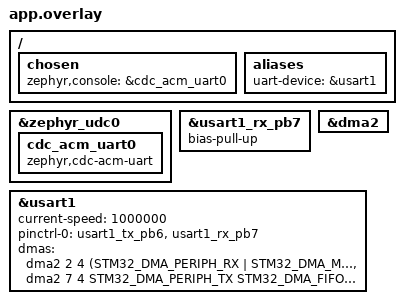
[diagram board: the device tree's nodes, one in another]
/*
 * Copyright (c) 2021 Nordic Semiconductor ASA
 *
 * SPDX-License-Identifier: Apache-2.0
 */

#include <zephyr/dt-bindings/dma/stm32_dma.h>

/ {
	chosen {
		zephyr,console = &cdc_acm_uart0;
	};

	aliases {
    	uart-device = &usart1;
    };
};

/*
&usbotg_fs {
    status = "okay";
    cdc_acm_uart0: cdc_acm_uart0 {
        compatible = "zephyr,cdc-acm-uart";
        label = "CDC_ACM_0";
    };
};
*/

&zephyr_udc0 {
	cdc_acm_uart0: cdc_acm_uart0 {
		compatible = "zephyr,cdc-acm-uart";
	};
};


/*
 * An idle UART line sits high. PB7 has no bias by default, so whenever nothing
 * drives it -- peer in reset, powered down, or cable out -- it floats and noise
 * reads as start bits, which surfaces as a slow trickle of framing errors.
 */
&usart1_rx_pb7 {
    bias-pull-up;
};

&dma2 {
    status = "okay";
};

&usart1 {
    status = "okay";
    /* Boot default only: the host's SET_LINE_CODING takes over once the port
     * is opened, unless BRIDGE_FOLLOW_HOST_LINE_CODING is turned off. */
    current-speed = <1000000>;
    pinctrl-0 = <&usart1_tx_pb6 &usart1_rx_pb7>;
    pinctrl-names = "default";

    /*
     * At 1 Mbaud a byte lands every ~10 us and this USART has no RX FIFO, so
     * interrupt-per-byte reception overruns whenever a longer ISR (USB) runs.
     * DMA2 stream 2 channel 4 is USART1_RX, stream 7 channel 4 is USART1_TX.
     *
     * RX is cyclic on purpose. Otherwise the driver ping-pongs between two
     * buffers, and uart_stm32_dma_replace_buffer() reloads the stream and
     * clears the IDLE flag around the switch; a byte arriving in that window
     * goes unreported until the next RX_RDY, so on a request/response protocol
     * one byte per buffer disappears until the peer speaks again. Cyclic mode
     * never switches buffers, so that path is never reached.
     */
    dmas = <&dma2 2 4 (STM32_DMA_PERIPH_RX | STM32_DMA_MODE_CYCLIC) STM32_DMA_FIFO_1_4>,
           <&dma2 7 4 STM32_DMA_PERIPH_TX STM32_DMA_FIFO_1_4>;
    dma-names = "rx", "tx";
};

